# CY8C4245AXI_483 register map
File version: 0.1
PSoC 4200
Registers are 32-bit, read-write, no defined reset value unless marked. A register's access mark holds for its fields unless they carry their own. Offsets are from the block's base; lines under a group give offsets from that group; [hi:lo] are bit positions; {n}, {i} and the like mark numbered series; 'fields as' and 'values as' point back to an identical list; <NAME> marks a mode.

## Memory map
0x00000000 Comp_H — Comparator
0x00000000 Comp_Z — Low Power Comparator
0x00000000 BUZZER
0x00000000 Reg_SSR
0x00000000 SSR
0x00000000 Comp_C — Comparator
0x00000000 ADC — Sequencing SAR ADC
0x00000000 UART — Serial Communication Block
0x00000000 PWM

## Comp_H — Comparator
Base 0x00000000
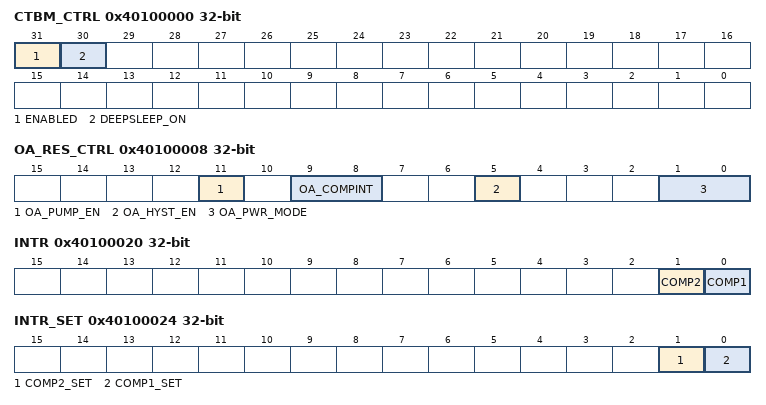
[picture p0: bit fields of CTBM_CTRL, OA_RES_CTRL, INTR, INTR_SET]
0x40100000 CTBM_CTRL — Global CTB IP and power control
  [31] ENABLED — Selects component behavior in DeepSleep power mode
    0=DISABLE (CTB IP disabled (put analog in power down, open all switches)); 1=ENABLE (CTB IP enabledCTB IP enabled)
  [30] DEEPSLEEP_ON — Selects component behavior in DeepSleep power mode
    0=DISABLE (CTB IP disabled off during DeepSleep power mode); 1=ENABLE (CTB IP remains enabled during DeepSleep power mode (if ENABLED=1))
0x40100008 OA_RES_CTRL — Comparator and resistor control
  [11] OA_PUMP_EN — Selects pump
    0=DISABLE (Pump disabled); 1=ENABLE (Pump enabled)
  [9:8] OA_COMPINT — Selects comparator edge detect
    0=DISABLE (Disabled); 1=RISING (Rising edge); 2=FALLING (Falling edge); 3=BOTH (Both rising and falling edges)
  [5] OA_HYST_EN — Selects hysteresis (10mV)
    0=DISABLE (Hysteresis disabled); 1=ENABLE (Hysteresis enabled)
  [1:0] OA_PWR_MODE — Selects speed for comparator
    0=OFF; 1=SLOW (Slow speed); 2=MED (Medium speed); 3=FAST (Fast speed)
0x4010000C COMP_STAT — Comparator status
  [16] OA_COMP ro — Current comparator status
0x40100020 INTR — Interrupt request register
  [1] COMP2 — Comparator #2 Interrupt: hardware sets this interrupt when comparator 0 triggers. Write with '1' to clear bit.
  [0] COMP1 — Comparator #1 Interrupt: hardware sets this interrupt when comparator 0 triggers. Write with '1' to clear bit.
0x40100024 INTR_SET — Interrupt request set register
  [1] COMP2_SET — Write with '1' to set corresponding bit in interrupt request register.
  [0] COMP1_SET — Write with '1' to set corresponding bit in interrupt request register.
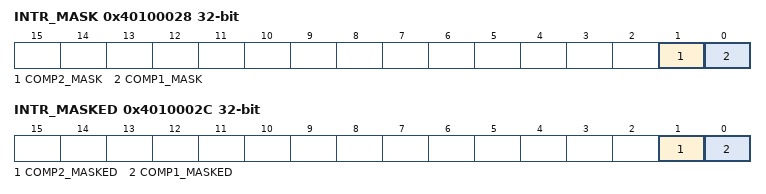
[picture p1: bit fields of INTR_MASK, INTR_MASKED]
0x40100028 INTR_MASK — Interrupt request mask
  [1] COMP2_MASK — Mask bit for corresponding bit in interrupt request register.
  [0] COMP1_MASK — Mask bit for corresponding bit in interrupt request register.
0x4010002C INTR_MASKED — Interrupt request masked
  [1] COMP2_MASKED ro — Logical and of corresponding request and mask bits.
  [0] COMP1_MASKED ro — Logical and of corresponding request and mask bits.
0x40100F0C OA_OFFSET_TRIM — Comparator offset trim
0x40100F10 OA_SLOPE_OFFSET_TRIM — Comparator slope offset drift trim
0x40100F14 OA_COMP_TRIM — Comparator trim

## Comp_C — Comparator
Base 0x00000000
Registers as Comp_H, without OA_RES_CTRL, OA_OFFSET_TRIM, OA_SLOPE_OFFSET_TRIM, OA_COMP_TRIM; these are added or differ:
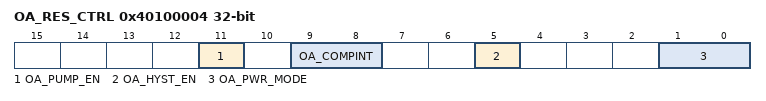
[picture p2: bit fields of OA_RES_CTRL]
0x40100004 OA_RES_CTRL — Comparator and resistor control
  fields as Comp_H.OA_RES_CTRL
0x40100F00 OA_OFFSET_TRIM — Comparator offset trim
0x40100F04 OA_SLOPE_OFFSET_TRIM — Comparator slope offset drift trim
0x40100F08 OA_COMP_TRIM — Comparator trim

## Comp_Z — Low Power Comparator
Base 0x00000000
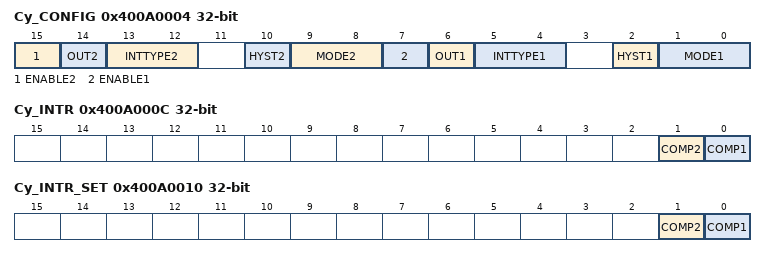
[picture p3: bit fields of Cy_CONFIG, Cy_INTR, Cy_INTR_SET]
0x400A0004 Cy_CONFIG — LPCOMP configuration
  [15] ENABLE2 — Enable comparator #2
    0=DISABLE (Comparator disabled); 1=ENABLE (Comparator enabled)
  [14] OUT2 ro — Current output value of the comparator #2
  [13:12] INTTYPE2 — Sets which edge will trigger an IRQ for the comparator #2
    0=DISABLE (Disabled); 1=RISING (Rising edge); 2=FALLING (Falling edge); 3=BOTH (Both rising and falling edges)
  [10] HYST2 — Selects hysteresis (10mV) for the comparator #2
    0=ENABLE (Hysteresis enabled); 1=DISABLE (Hysteresis disabled)
  [9:8] MODE2 — Selects speed for the comparator #2
    0=MED (Medium speed); 1=FAST (Fast speed); 2=SLOW (Slow speed)
  [7] ENABLE1 — Enable comparator #1
    values as ENABLE2
  [6] OUT1 ro — Current output value of the comparator
  [5:4] INTTYPE1 — Sets which edge will trigger an IRQ for the comparator #1
    values as INTTYPE2
  [2] HYST1 — Selects hysteresis (10mV) for the comparator #1
    values as HYST2
  [1:0] MODE1 — Selects speed for the comparator #1
    values as MODE2
0x400A000C Cy_INTR — LPCOMP interrupt
  [1] COMP2 — Comparator #2 Interrupt: hardware sets this interrupt when comparator 0 triggers. Write with '1' to clear bit.
  [0] COMP1 — Comparator #1 Interrupt: hardware sets this interrupt when comparator 0 triggers. Write with '1' to clear bit.
0x400A0010 Cy_INTR_SET — LPCOMP interrupt set register
  [1] COMP2 — Write with '1' to set corresponding bit in interrupt request register.
  [0] COMP1 — Write with '1' to set corresponding bit in interrupt request register.
0x400AFF00 Cy_TRIM_A — LPCOMP trim A
0x400AFF04 Cy_TRIM_B — LPCOMP trim B
